# NAVSS0_MODSS_INTA0_CFG register map
Vendor: Texas Instruments
Peripheral module from a debugger description file (folder J7ES).
Registers are 64-bit, read-only, reset 0x66965100 unless marked. A register's access mark holds for its fields unless they carry their own. Offsets are as the file gives them; lines under a group give offsets from that group; [hi:lo] are bit positions; {n}, {i} and the like mark numbered series; 'fields as' and 'values as' point back to an identical list; <NAME> marks a mode.

## NAVSS0_MODSS_INTA0_CFG
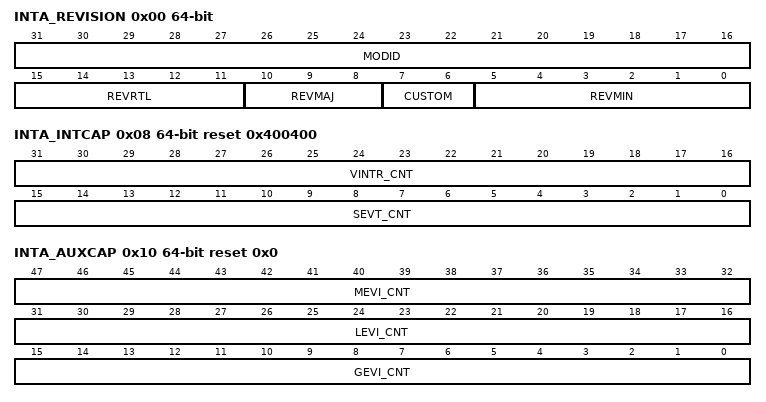
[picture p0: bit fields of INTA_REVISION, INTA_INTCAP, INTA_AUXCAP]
0x00 INTA_REVISION — The Revision Register contains the major and minor revisions for the module.
  [31:16] MODID — Module ID field
  [15:11] REVRTL — RTL Revision. Will vary depending on release.
  [10:8] REVMAJ — Major Revision
  [7:6] CUSTOM
  [5:0] REVMIN — Minor Revision
0x08 INTA_INTCAP reset 0x400400 — The IntCap Register contains information on virtual interrupts.
  [31:16] VINTR_CNT — Virtual interrupt register/pin count
  [15:0] SEVT_CNT — Number of 'event to virt int' mapping registers
0x10 INTA_AUXCAP reset 0x0 — The AuxCap Register contains information on additional capabilities.
  [47:32] MEVI_CNT — Number of multicast event registers
  [31:16] LEVI_CNT — Local input events for local to global translation
  [15:0] GEVI_CNT — Number of event counting registers
